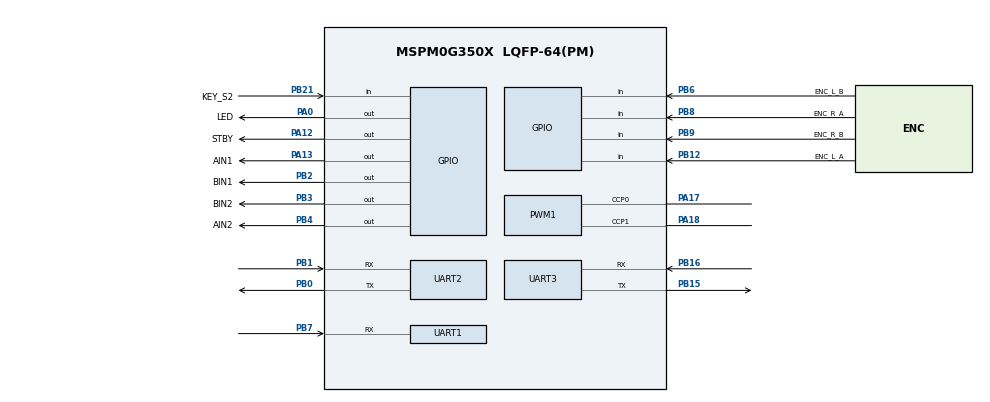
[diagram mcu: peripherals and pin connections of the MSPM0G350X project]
/**
 * @cliArgs --device "MSPM0G350X" --part "Default" --package "LQFP-64(PM)" --product "mspm0_sdk@2.10.00.04"
 * @versions {"tool":"1.26.2+4477"}
 */

/**
 * Import the modules used in this configuration.
 */
const GPIO   = scripting.addModule("/ti/driverlib/GPIO", {}, false);
const GPIO1  = GPIO.addInstance();
const GPIO2  = GPIO.addInstance();
const GPIO3  = GPIO.addInstance();
const GPIO4  = GPIO.addInstance();
const GPIO5  = GPIO.addInstance();
const GPIO6  = GPIO.addInstance();
const PWM    = scripting.addModule("/ti/driverlib/PWM", {}, false);
const PWM1   = PWM.addInstance();
const SYSCTL = scripting.addModule("/ti/driverlib/SYSCTL");
const TIMER  = scripting.addModule("/ti/driverlib/TIMER", {}, false);
const TIMER1 = TIMER.addInstance();
const TIMER2 = TIMER.addInstance();
const UART   = scripting.addModule("/ti/driverlib/UART", {}, false);
const UART1  = UART.addInstance();
const UART2  = UART.addInstance();
const UART3  = UART.addInstance();

/**
 * Write custom configuration values to the imported modules.
 */
GPIO1.$name                              = "ENCODER_RIGHT_A";
GPIO1.associatedPins[0].$name            = "ENC_R_A";
GPIO1.associatedPins[0].direction        = "INPUT";
GPIO1.associatedPins[0].internalResistor = "PULL_UP";
GPIO1.associatedPins[0].interruptEn      = true;
GPIO1.associatedPins[0].polarity         = "RISE_FALL";
GPIO1.associatedPins[0].pin.$assign      = "PB8";

const Board = scripting.addModule("/ti/driverlib/Board", {}, false);

GPIO2.$name                              = "ENCODER_RIGHT_B";
GPIO2.associatedPins[0].$name            = "ENC_R_B";
GPIO2.associatedPins[0].direction        = "INPUT";
GPIO2.associatedPins[0].internalResistor = "PULL_UP";
GPIO2.associatedPins[0].interruptEn      = true;
GPIO2.associatedPins[0].polarity         = "RISE_FALL";
GPIO2.associatedPins[0].pin.$assign      = "PB9";

GPIO3.$name                         = "GPIO_MOTOR_DIR";
GPIO3.associatedPins.create(5);
GPIO3.associatedPins[0].$name       = "STBY";
GPIO3.associatedPins[0].pin.$assign = "PA12";
GPIO3.associatedPins[1].$name       = "AIN1";
GPIO3.associatedPins[1].pin.$assign = "PA13";
GPIO3.associatedPins[2].$name       = "AIN2";
GPIO3.associatedPins[2].pin.$assign = "PB4";
GPIO3.associatedPins[3].$name       = "BIN1";
GPIO3.associatedPins[3].pin.$assign = "PB2";
GPIO3.associatedPins[4].$name       = "BIN2";
GPIO3.associatedPins[4].pin.$assign = "PB3";

GPIO4.$name                              = "ENCODER_LEFT_A";
GPIO4.associatedPins[0].$name            = "ENC_L_A";
GPIO4.associatedPins[0].direction        = "INPUT";
GPIO4.associatedPins[0].internalResistor = "PULL_UP";
GPIO4.associatedPins[0].interruptEn      = true;
GPIO4.associatedPins[0].polarity         = "RISE_FALL";
GPIO4.associatedPins[0].pin.$assign      = "PB12";

GPIO5.$name                              = "ENCODER_LEFT_B";
GPIO5.associatedPins[0].$name            = "ENC_L_B";
GPIO5.associatedPins[0].direction        = "INPUT";
GPIO5.associatedPins[0].internalResistor = "PULL_UP";
GPIO5.associatedPins[0].interruptEn      = true;
GPIO5.associatedPins[0].polarity         = "RISE_FALL";
GPIO5.associatedPins[0].pin.$assign      = "PB6";

GPIO6.$name                              = "GPIO_UI";
GPIO6.associatedPins.create(2);
GPIO6.associatedPins[0].$name            = "KEY_S2";
GPIO6.associatedPins[0].direction        = "INPUT";
GPIO6.associatedPins[0].internalResistor = "PULL_UP";
GPIO6.associatedPins[0].pin.$assign      = "PB21";
GPIO6.associatedPins[1].$name            = "LED";
GPIO6.associatedPins[1].direction        = "OUTPUT";
GPIO6.associatedPins[1].pin.$assign      = "PA0";

PWM1.$name                              = "PWM_MOTOR";
PWM1.timerCount                         = 1600;
PWM1.peripheral.$assign                 = "TIMG7";
PWM1.peripheral.ccp0Pin.$assign         = "PA17";
PWM1.peripheral.ccp1Pin.$assign         = "PA18";
PWM1.PWM_CHANNEL_0.$name                = "ti_driverlib_pwm_PWMTimerCC0";
PWM1.PWM_CHANNEL_1.$name                = "ti_driverlib_pwm_PWMTimerCC1";
PWM1.ccp0PinConfig.direction            = scripting.forceWrite("OUTPUT");
PWM1.ccp0PinConfig.hideOutputInversion  = scripting.forceWrite(false);
PWM1.ccp0PinConfig.onlyInternalResistor = scripting.forceWrite(false);
PWM1.ccp0PinConfig.passedPeripheralType = scripting.forceWrite("Digital");
PWM1.ccp0PinConfig.$name                = "ti_driverlib_gpio_GPIOPinGeneric7";
PWM1.ccp1PinConfig.direction            = scripting.forceWrite("OUTPUT");
PWM1.ccp1PinConfig.hideOutputInversion  = scripting.forceWrite(false);
PWM1.ccp1PinConfig.onlyInternalResistor = scripting.forceWrite(false);
PWM1.ccp1PinConfig.passedPeripheralType = scripting.forceWrite("Digital");
PWM1.ccp1PinConfig.$name                = "ti_driverlib_gpio_GPIOPinGeneric8";

SYSCTL.forceDefaultClkConfig = true;

TIMER1.$name              = "SCHEDULE_TIMER";
TIMER1.timerPeriod        = "1 ms";
TIMER1.timerMode          = "PERIODIC";
TIMER1.interrupts         = ["ZERO"];
TIMER1.peripheral.$assign = "TIMG0";

TIMER2.$name              = "QEI_SAMPLE_TIMER";
TIMER2.timerPeriod        = "1 ms";
TIMER2.timerMode          = "PERIODIC";
TIMER2.interrupts         = ["ZERO"];
TIMER2.peripheral.$assign = "TIMG12";

UART1.$name                            = "UART_WIT";
UART1.targetBaudRate                   = 115200;
UART1.enableFIFO                       = true;
UART1.direction                        = "RX";
UART1.rxTimeoutValue                   = 1;
UART1.rxFifoThreshold                  = "DL_UART_RX_FIFO_LEVEL_ONE_ENTRY";
UART1.enabledInterrupts                = ["RX_TIMEOUT_ERROR"];
UART1.enabledDMARXTriggers             = "DL_UART_DMA_INTERRUPT_RX";
UART1.rxPinConfig.hideOutputInversion  = scripting.forceWrite(false);
UART1.rxPinConfig.onlyInternalResistor = scripting.forceWrite(false);
UART1.rxPinConfig.passedPeripheralType = scripting.forceWrite("Digital");
UART1.rxPinConfig.$name                = "ti_driverlib_gpio_GPIOPinGeneric1";
UART1.peripheral.$assign               = "UART1";
UART1.peripheral.rxPin.$assign         = "PB7";
UART1.DMA_CHANNEL_RX.$name             = "DMA_WIT";
UART1.DMA_CHANNEL_RX.addressMode       = "f2b";
UART1.DMA_CHANNEL_RX.srcLength         = "BYTE";
UART1.DMA_CHANNEL_RX.dstLength         = "BYTE";

UART2.$name                            = "UART_Blue";
UART2.targetBaudRate                   = 115200;
UART2.enableFIFO                       = true;
UART2.rxFifoThreshold                  = "DL_UART_RX_FIFO_LEVEL_ONE_ENTRY";
UART2.txFifoThreshold                  = "DL_UART_TX_FIFO_LEVEL_ONE_ENTRY";
UART2.rxTimeoutValue                   = 1;
UART2.enabledInterrupts                = ["RX_TIMEOUT_ERROR"];
UART2.enabledDMARXTriggers             = "DL_UART_DMA_INTERRUPT_RX";
UART2.enabledDMATXTriggers             = "DL_UART_DMA_INTERRUPT_TX";
UART2.peripheral.$assign               = "UART0";
UART2.peripheral.rxPin.$assign         = "PB1";
UART2.peripheral.txPin.$assign         = "PB0";
UART2.txPinConfig.direction            = scripting.forceWrite("OUTPUT");
UART2.txPinConfig.hideOutputInversion  = scripting.forceWrite(false);
UART2.txPinConfig.onlyInternalResistor = scripting.forceWrite(false);
UART2.txPinConfig.passedPeripheralType = scripting.forceWrite("Digital");
UART2.txPinConfig.$name                = "ti_driverlib_gpio_GPIOPinGeneric2";
UART2.rxPinConfig.hideOutputInversion  = scripting.forceWrite(false);
UART2.rxPinConfig.onlyInternalResistor = scripting.forceWrite(false);
UART2.rxPinConfig.passedPeripheralType = scripting.forceWrite("Digital");
UART2.rxPinConfig.$name                = "ti_driverlib_gpio_GPIOPinGeneric3";
UART2.DMA_CHANNEL_RX.$name             = "DMA_RX_Blue";
UART2.DMA_CHANNEL_RX.srcLength         = "BYTE";
UART2.DMA_CHANNEL_RX.dstLength         = "BYTE";
UART2.DMA_CHANNEL_TX.$name             = "DMA_TX_Blue";
UART2.DMA_CHANNEL_TX.addressMode       = "b2f";
UART2.DMA_CHANNEL_TX.srcLength         = "BYTE";
UART2.DMA_CHANNEL_TX.dstLength         = "BYTE";

UART3.$name                            = "UART_Track";
UART3.targetBaudRate                   = 115200;
UART3.enableFIFO                       = true;
UART3.rxFifoThreshold                  = "DL_UART_RX_FIFO_LEVEL_ONE_ENTRY";
UART3.txFifoThreshold                  = "DL_UART_TX_FIFO_LEVEL_ONE_ENTRY";
UART3.rxTimeoutValue                   = 1;
UART3.enabledInterrupts                = ["RX_TIMEOUT_ERROR"];
UART3.enabledDMARXTriggers             = "DL_UART_DMA_INTERRUPT_RX";
UART3.enabledDMATXTriggers             = "DL_UART_DMA_INTERRUPT_TX";
UART3.peripheral.$assign               = "UART2";
UART3.peripheral.rxPin.$assign         = "PB16";
UART3.peripheral.txPin.$assign         = "PB15";
UART3.txPinConfig.direction            = scripting.forceWrite("OUTPUT");
UART3.txPinConfig.hideOutputInversion  = scripting.forceWrite(false);
UART3.txPinConfig.onlyInternalResistor = scripting.forceWrite(false);
UART3.txPinConfig.passedPeripheralType = scripting.forceWrite("Digital");
UART3.txPinConfig.$name                = "ti_driverlib_gpio_GPIOPinGeneric4";
UART3.rxPinConfig.hideOutputInversion  = scripting.forceWrite(false);
UART3.rxPinConfig.onlyInternalResistor = scripting.forceWrite(false);
UART3.rxPinConfig.passedPeripheralType = scripting.forceWrite("Digital");
UART3.rxPinConfig.$name                = "ti_driverlib_gpio_GPIOPinGeneric5";
UART3.DMA_CHANNEL_RX.$name             = "DMA_RX_Track";
UART3.DMA_CHANNEL_RX.addressMode       = "f2b";
UART3.DMA_CHANNEL_RX.srcLength         = "BYTE";
UART3.DMA_CHANNEL_RX.dstLength         = "BYTE";
UART3.DMA_CHANNEL_TX.$name             = "DMA_TX_Track";
UART3.DMA_CHANNEL_TX.addressMode       = "b2f";
UART3.DMA_CHANNEL_TX.srcLength         = "BYTE";
UART3.DMA_CHANNEL_TX.dstLength         = "BYTE";

/**
 * Pinmux solution for unlocked pins/peripherals. This ensures that minor changes to the automatic solver in a future
 * version of the tool will not impact the pinmux you originally saw.  These lines can be completely deleted in order to
 * re-solve from scratch.
 */
Board.peripheral.$suggestSolution                = "DEBUGSS";
Board.peripheral.swclkPin.$suggestSolution       = "PA20";
Board.peripheral.swdioPin.$suggestSolution       = "PA19";
SYSCTL.peripheral.$suggestSolution               = "SYSCTL";
UART1.DMA_CHANNEL_RX.peripheral.$suggestSolution = "DMA_CH4";
UART2.DMA_CHANNEL_RX.peripheral.$suggestSolution = "DMA_CH3";
UART2.DMA_CHANNEL_TX.peripheral.$suggestSolution = "DMA_CH2";
UART3.DMA_CHANNEL_RX.peripheral.$suggestSolution = "DMA_CH1";
UART3.DMA_CHANNEL_TX.peripheral.$suggestSolution = "DMA_CH0";
